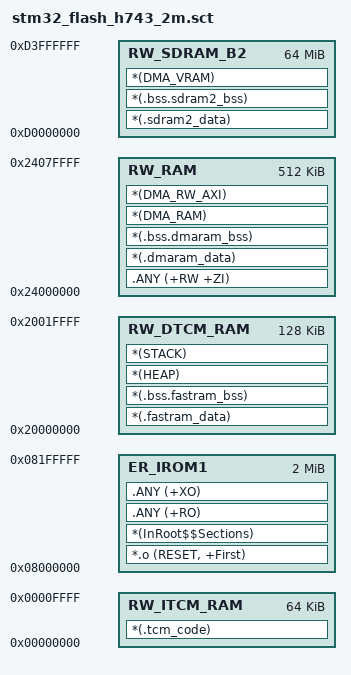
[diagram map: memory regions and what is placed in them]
; *************************************************************
; *** Scatter-Loading Description File generated by uVision ***
; *************************************************************

LR_IROM1 0x08000000 0x00200000  {    ; load region size_region
  ER_IROM1 0x08000000 0x00200000  {  ; load address = execution address
   *.o (RESET, +First)
   *(InRoot$$Sections)
   .ANY (+RO)
   .ANY (+XO)
  }
  RW_ITCM_RAM 0x00000000 0x00010000 {
   *(.tcm_code)
  }
  RW_DTCM_RAM 0x20000000 0x00020000 {  ; RW data
   *(.fastram_data)
   *(.bss.fastram_bss)
   *(HEAP)
   *(STACK)
  }
  RW_RAM 0x24000000 0x00080000      {
   .ANY (+RW +ZI)
   *(.dmaram_data)
   *(.bss.dmaram_bss)
   *(DMA_RAM)
   *(DMA_RW_AXI)
  }
  RW_SDRAM_B2 0xD0000000 0x04000000 {
   *(.sdram2_data)
   *(.bss.sdram2_bss)
   *(DMA_VRAM)
  }
}
